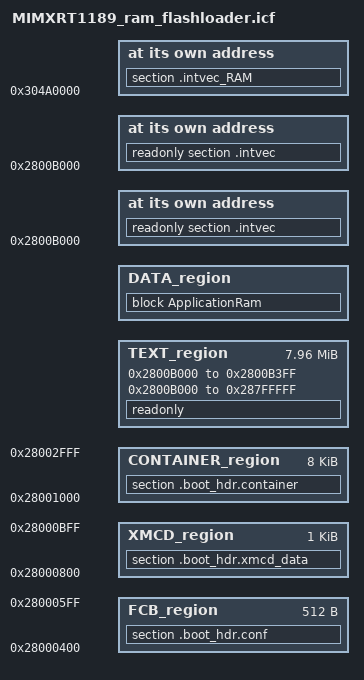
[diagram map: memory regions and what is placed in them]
/*
** ###################################################################
**     Abstract:
**         Linker file for the IAR ANSI C/C++ Compiler for ARM
**
**     Copyright 2016-2022 NXP
**
**     All rights reserved.
**
**     SPDX-License-Identifier: BSD-3-Clause
**
**
** ###################################################################
*/

define symbol __ram_vector_table_size__        =  isdefinedsymbol(__ram_vector_table__) ? 0x00000400 : 0;
define symbol __ram_vector_table_offset__      =  isdefinedsymbol(__ram_vector_table__) ? 0x000003FF : 0;


define symbol m_flash_start            = 0x28000000;
define symbol m_flash_size             = 0x00800000;

/* General definition */
define symbol m_fcb_offset             = 0x400;
define symbol m_fcb_size               = 0x200;
define symbol m_fcb_start              = m_flash_start + m_fcb_offset;
define symbol m_fcb_end                = m_fcb_start + m_fcb_size - 1;

define symbol m_xmcd_offset            = 0x800;
define symbol m_xmcd_size              = 0x400;
define symbol m_xmcd_start             = m_flash_start + m_xmcd_offset;
define symbol m_xmcd_end               = m_xmcd_start + m_xmcd_size - 1;

define symbol m_container_offset       = 0x1000;
define symbol m_container_size         = 0x2000;
define symbol m_container_start        = m_flash_start + m_container_offset;
define symbol m_container_end          = m_container_start + m_container_size - 1;

define symbol app_image_offset         = 0x0000B000;
define symbol vector_table_size        = 0x00000400;
/* Sizes */
if (isdefinedsymbol(__stack_size__)) {
  define symbol __size_cstack__        = __stack_size__;
} else {
  define symbol __size_cstack__        = 0x1000;
}

if (isdefinedsymbol(__heap_size__)) {
  define symbol __size_heap__          = __heap_size__;
} else {
  define symbol __size_heap__          = 0;
}

define symbol m_code_size              = m_flash_size - app_image_offset;
define symbol m_text_start             = m_flash_start + app_image_offset;
define symbol m_text_end               = m_text_start + m_code_size - 1;

define symbol m_interrupts_start       = m_text_start;
define symbol m_interrupts_end         = m_text_start + 0x3FF;

define symbol m_interrupts_ram_start   = 0x304A0000;
define symbol m_interrupts_ram_end     = 0x304A0000 + __ram_vector_table_offset__;

define symbol m_data_start             = m_interrupts_ram_start + __ram_vector_table_size__;
define symbol m_data_end               = 0x304C7FFF;

define memory mem with size = 4G;
define region FCB_region       = mem:[from m_fcb_start to m_fcb_end];
define region XMCD_region      = mem:[from m_xmcd_start to m_xmcd_end];
define region CONTAINER_region = mem:[from m_container_start to m_container_end];
define region TEXT_region = mem:[from m_interrupts_start to m_interrupts_end]
                          | mem:[from m_text_start to m_text_end];
define region DATA_region = mem:[from m_data_start to m_data_end];

define exported symbol __VECTOR_TABLE  = m_interrupts_start;
define exported symbol __VECTOR_RAM    = isdefinedsymbol(__ram_vector_table__) ? m_interrupts_ram_start : m_interrupts_start;
define exported symbol __RAM_VECTOR_TABLE_SIZE = __ram_vector_table_size__;
define exported symbol __CONTAINER_IMG_OFFSET     = start(TEXT_region) - start(CONTAINER_region);
define exported symbol __CONTAINER_IMG_LOAD_ADDR  = start(TEXT_region);
define exported symbol __CONTAINER_IMG_ENTRY_ADDR = start(TEXT_region);

define block CSTACK    with alignment = 8, size = __size_cstack__   { };
define block HEAP      with alignment = 8, size = __size_heap__     { };

initialize by copy { readwrite };
initialize by copy { section .data};
initialize by copy { section .textrw };
initialize by copy { readonly } 
    except { 
        section .boot_hdr.conf,
        section .boot_hdr.xmcd_data,
        section .boot_hdr.container};
do not initialize  { section .noinit };

//define block CodeRelocate { section .textrw_init };
define block CodeRelocateRam { section .textrw };
//define block ApplicationFlash { readonly, block CodeRelocate, readonly section .noinit };
define block ApplicationRam { readwrite, block CodeRelocateRam, block CSTACK, block HEAP};
place at address mem: m_interrupts_start    { readonly section .intvec };
place in FCB_region                         { section .boot_hdr.conf };
place in XMCD_region                        { section .boot_hdr.xmcd_data };
place in CONTAINER_region                   { section .boot_hdr.container };

keep{ section .boot_hdr.conf, section .boot_hdr.xmcd_data, section .boot_hdr.container };
//place in TEXT_region { block ApplicationFlash };
place at address mem:m_interrupts_ram_start   { section .intvec_RAM };
place at address mem:m_text_start             { readonly section .intvec };
place in TEXT_region                          { readonly };
place in DATA_region { block ApplicationRam };
